AUTOSAR XML (schema 4-2-2)
package /Components
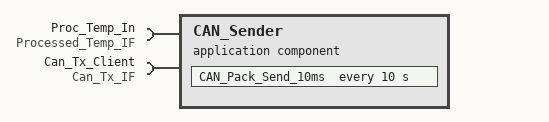
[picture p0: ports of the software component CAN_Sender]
  application sw component type CAN_Sender
    require port Proc_Temp_In: required-interface=Processed_Temp_IF
    require port Can_Tx_Client: required-interface=Can_Tx_IF
    behavior CAN_Sender_InternalBehavior
      init event CAN_Init_Event: start-on-event=CAN_Pack_Send_10ms
      timing event CAN_10ms_Event: start-on-event=CAN_Pack_Send_10ms, period=10
      runnable CAN_Pack_Send_10ms: minimum-start-interval=10
        data-receive-point-by-arguments:
          access VA_Temp{1..3}_Proc_In: accessed-variable=Proc_Temp_In.Temp{1..3}_Proc
        sync call SCP_Send_Temp_CanFrame: operation=Can_Tx_Client.Send_Temp_CanFrame, timeout=5
